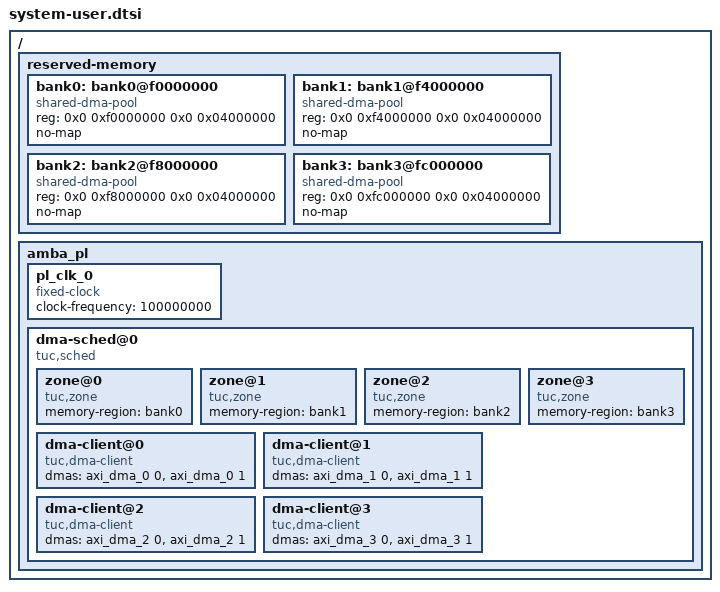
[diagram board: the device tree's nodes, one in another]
/include/ "system-conf.dtsi"
/  {
	reserved-memory {
		#address-cells = <2>;
		#size-cells = <2>;
		ranges;

		bank0: bank0@f0000000 {
			reg = <0x0 0xf0000000 0x0 0x04000000>;
			compatible = "shared-dma-pool";
			no-map;
		};
		bank1: bank1@f4000000 {
			reg = <0x0 0xf4000000 0x0 0x04000000>;
			compatible = "shared-dma-pool";
			no-map;
		};
		bank2: bank2@f8000000 {
			reg = <0x0 0xf8000000 0x0 0x04000000>;
			compatible = "shared-dma-pool";
			no-map;
		};
		bank3: bank3@fc000000 {
			reg = <0x0 0xfc000000 0x0 0x04000000>;
			compatible = "shared-dma-pool";
			no-map;
		};
	};

	amba_pl {
		pl_clk_0: pl_clk_0 {
			compatible = "fixed-clock";
			#clock-cells = <0>;
			clock-frequency = <100000000>;
		};

		dma-sched@0 {
			compatible = "tuc,sched";

			zone@0 {
				compatible = "tuc,zone";
				memory-region = <&bank0>;
			};
			zone@1 {
				compatible = "tuc,zone";
				memory-region = <&bank1>;
			};
			zone@2 {
				compatible = "tuc,zone";
				memory-region = <&bank2>;
			};
			zone@3 {
				compatible = "tuc,zone";
				memory-region = <&bank3>;
			};

			dma-client@0 {
				compatible = "tuc,dma-client";
				dmas = <&axi_dma_0 0
					&axi_dma_0 1>;
				dma-names = "tx", "rx";
			};
			dma-client@1 {
				compatible = "tuc,dma-client";
				dmas = <&axi_dma_1 0
					&axi_dma_1 1>;
				dma-names = "tx", "rx";
			};
			dma-client@2 {
				compatible = "tuc,dma-client";
				dmas = <&axi_dma_2 0
					&axi_dma_2 1>;
				dma-names = "tx", "rx";
			};
			dma-client@3 {
				compatible = "tuc,dma-client";
				dmas = <&axi_dma_3 0
					&axi_dma_3 1>;
				dma-names = "tx", "rx";
			};
		};
	};
};

